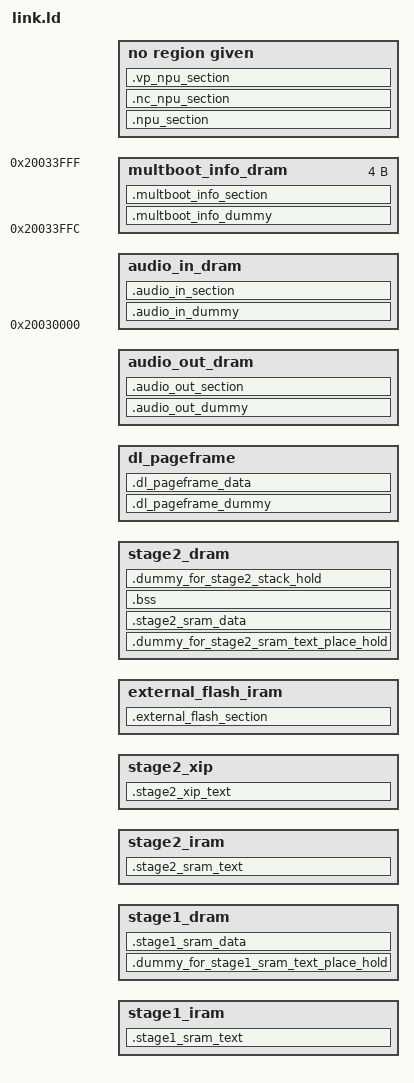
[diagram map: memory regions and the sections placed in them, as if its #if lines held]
#include<autoconf.h>
#include<autogenerated_config.h>
#include<board_config.h>
#include<base_addr.h>
#include<lib/sizes.h>

#ifdef CONFIG_BOOT_BY_UART
#define HEAD_LENGTH 0
#define STAGE2_HEAD_LENGTH 0
#else
#define HEAD_LENGTH 24
#define STAGE2_HEAD_LENGTH 4
#endif

#ifdef CONFIG_BOARD_SUPPORT_MULTIBOOT
#define MULTIBOOT_INFO_SIZE 4
#endif

#define STAGE2_TEXT       *(.text*)
#define STAGE2_DATA       *(.data*)
#define STAGE2_RODATA     *(.rodata*)
#define STAGE2_XIP_TEXT   *(.xip.text)
#define STAGE2_XIP_RODATA *(.xip.rodata*)

# define RUN_AT_STAGE2_TEXT (tmp_objs/vic.o \
                            CONFIG_BOARD_PATH/clock_board.o \
                            tmp_objs/flash_spi.o \
                            tmp_objs/spi_nor_ids.o \
                            tmp_objs/flash.o  \
                            tmp_objs/pmu_ctrl.o \
                            tmp_objs/pmu_osc.o \
                            tmp_objs/ldo.o \
                            tmp_objs/clock.o \
                            arch/cpu/csky/ck804/start.o \
                            arch/cpu/csky/ck804/spl_start.o \
                            arch/soc/grus/system.o \
                            arch/soc/grus/trap_c.o \
                            arch/soc/grus/vectors.o \
                            tmp_objs/systick_counter.o \
                            tmp_objs/gx_counter.o \
                            tmp_objs/gx_dcache.o \
                            utility/libc/csky/memcpy.o \
                            utility/libc/csky/memcpy_fast.o \
                            utility/libc/csky/memset.o \
                            utility/libc/csky/memset_fast.o \
                            utility/libm/csky/ef_exp.o \
                            utility/libm/csky/wf_exp.o \
                            tmp_objs/gx_icache.o)

/* LMA */
#ifdef CONFIG_MCU_ENABLE_JTAG_DEBUG
# define STAGE1_SRAM_TEXT_LMA
# define STAGE1_SRAM_DATA_LMA
# define STAGE2_XIP_TEXT_LMA
# define STAGE2_SRAM_TEXT_LMA
# define STAGE2_SRAM_DATA_LMA
# define NPU_LMA
# define NC_NPU_LMA
# define VP_NPU_LMA
# define EXTERNAL_FLASH_LMA
    LD_NPU_IMAGE_OFFSET     =    0;
    LD_NC_NPU_IMAGE_OFFSET  =    0;
    LD_VP_NPU_IMAGE_OFFSET  =    0;
    LD_MCU_END_IMAGE_OFFSET =    0;
#else
# define STAGE1_SRAM_TEXT_LMA   AT(0)
# define STAGE1_SRAM_DATA_LMA   AT(SIZEOF(.stage1_sram_text))

# ifdef CONFIG_MCU_ENABLE_XIP

#  define STAGE2_XIP_TEXT_LMA   AT(LENGTH(stage1_dram)+STAGE2_HEAD_LENGTH-HEAD_LENGTH)
#  define STAGE2_SRAM_TEXT_LMA  AT(LENGTH(stage1_dram)+STAGE2_HEAD_LENGTH-HEAD_LENGTH+SIZEOF(.stage2_xip_text))
#  define STAGE2_SRAM_DATA_LMA  AT(LENGTH(stage1_dram)+STAGE2_HEAD_LENGTH-HEAD_LENGTH+SIZEOF(.stage2_xip_text)+SIZEOF(.stage2_sram_text))
#  define NPU_LMA               AT(LENGTH(stage1_dram)+STAGE2_HEAD_LENGTH-HEAD_LENGTH+SIZEOF(.stage2_xip_text)+SIZEOF(.stage2_sram_text)+SIZEOF(.stage2_sram_data))
#  define NC_NPU_LMA            AT(LENGTH(stage1_dram)+STAGE2_HEAD_LENGTH-HEAD_LENGTH+SIZEOF(.stage2_xip_text)+SIZEOF(.stage2_sram_text)+SIZEOF(.stage2_sram_data) \
                                    +SIZEOF(.npu_section))
#  define VP_NPU_LMA            AT(LENGTH(stage1_dram)+STAGE2_HEAD_LENGTH-HEAD_LENGTH+SIZEOF(.stage2_xip_text)+SIZEOF(.stage2_sram_text)+SIZEOF(.stage2_sram_data) \
                                    +SIZEOF(.npu_section)+SIZEOF(.nc_npu_section))
#  define EXTERNAL_FLASH_LMA    AT(0x80000 -HEAD_LENGTH)

#  ifndef CONFIG_NPU_RUN_IN_FLASH
        LD_NPU_IMAGE_OFFSET    =    LENGTH(stage1_dram)+STAGE2_HEAD_LENGTH+SIZEOF(.stage2_xip_text)+SIZEOF(.stage2_sram_text)+SIZEOF(.stage2_sram_data);

        LD_NC_NPU_IMAGE_OFFSET =    LENGTH(stage1_dram)+STAGE2_HEAD_LENGTH+SIZEOF(.stage2_xip_text)+SIZEOF(.stage2_sram_text)+SIZEOF(.stage2_sram_data)
#   ifdef CONFIG_LVP_ENABLE_KEYWORD_RECOGNITION
                                    +SIZEOF(.npu_section)
#   endif
                                    ;

        LD_VP_NPU_IMAGE_OFFSET =    LENGTH(stage1_dram)+STAGE2_HEAD_LENGTH+SIZEOF(.stage2_xip_text)+SIZEOF(.stage2_sram_text)+SIZEOF(.stage2_sram_data)
#   ifdef CONFIG_LVP_ENABLE_KEYWORD_RECOGNITION
                                    +SIZEOF(.npu_section)
#   endif
#   if (defined CONFIG_LVP_ENABLE_NN_DENOISE) || (defined CONFIG_LVP_ENABLE_SED)
                                    +SIZEOF(.nc_npu_section)
#   endif
                                    ;
#  endif

   LD_MCU_END_IMAGE_OFFSET     =    LENGTH(stage1_dram)+STAGE2_HEAD_LENGTH+SIZEOF(.stage2_xip_text)+SIZEOF(.stage2_sram_text)+SIZEOF(.stage2_sram_data)
#  ifndef CONFIG_NPU_RUN_IN_FLASH
#   ifdef CONFIG_LVP_ENABLE_KEYWORD_RECOGNITION
                                    +SIZEOF(.npu_section)
#   endif
#   if (defined CONFIG_LVP_ENABLE_NN_DENOISE) || (defined CONFIG_LVP_ENABLE_SED)
                                    +SIZEOF(.nc_npu_section)
#   endif
#   ifdef CONFIG_LVP_ENABLE_VOICEPRINT_RECOGNITION
                                    +SIZEOF(.vp_npu_section)
#   endif
#  endif
                                    ;

# else
#  define STAGE2_XIP_TEXT_LMA
#  define STAGE2_SRAM_TEXT_LMA  AT(LENGTH(stage1_dram)+STAGE2_HEAD_LENGTH-HEAD_LENGTH)
#  define STAGE2_SRAM_DATA_LMA  AT(LENGTH(stage1_dram)+STAGE2_HEAD_LENGTH-HEAD_LENGTH+SIZEOF(.stage2_sram_text))
#  define NPU_LMA               AT(LENGTH(stage1_dram)+STAGE2_HEAD_LENGTH-HEAD_LENGTH+SIZEOF(.stage2_sram_text)+SIZEOF(.stage2_sram_data))
#  define NC_NPU_LMA            AT(LENGTH(stage1_dram)+STAGE2_HEAD_LENGTH-HEAD_LENGTH+SIZEOF(.stage2_sram_text)+SIZEOF(.stage2_sram_data)\
                                    +SIZEOF(.npu_section))
#  define VP_NPU_LMA            AT(LENGTH(stage1_dram)+STAGE2_HEAD_LENGTH-HEAD_LENGTH+SIZEOF(.stage2_sram_text)+SIZEOF(.stage2_sram_data)\
                                    +SIZEOF(.npu_section)+SIZEOF(.nc_npu_section))
#  define EXTERNAL_FLASH_LMA    AT(0x80000 +STAGE2_HEAD_LENGTH-HEAD_LENGTH)

#  ifndef CONFIG_NPU_RUN_IN_FLASH
        LD_NPU_IMAGE_OFFSET    =    LENGTH(stage1_dram)+STAGE2_HEAD_LENGTH+SIZEOF(.stage2_sram_text)+SIZEOF(.stage2_sram_data);

        LD_NC_NPU_IMAGE_OFFSET =    LENGTH(stage1_dram)+STAGE2_HEAD_LENGTH+SIZEOF(.stage2_sram_text)+SIZEOF(.stage2_sram_data)
#   ifdef CONFIG_LVP_ENABLE_KEYWORD_RECOGNITION
                                    +SIZEOF(.npu_section)
#   endif
                                    ;

        LD_VP_NPU_IMAGE_OFFSET =    LENGTH(stage1_dram)+STAGE2_HEAD_LENGTH+SIZEOF(.stage2_sram_text)+SIZEOF(.stage2_sram_data)
#   ifdef CONFIG_LVP_ENABLE_KEYWORD_RECOGNITION
                                    +SIZEOF(.npu_section)
#   endif
#   if (defined CONFIG_LVP_ENABLE_NN_DENOISE) || (defined CONFIG_LVP_ENABLE_SED)
                                    +SIZEOF(.nc_npu_section)
#   endif
                                    ;

    LD_MCU_END_IMAGE_OFFSET     =    LENGTH(stage1_dram)+STAGE2_HEAD_LENGTH+SIZEOF(.stage2_sram_text)+SIZEOF(.stage2_sram_data)
#   ifdef CONFIG_LVP_ENABLE_KEYWORD_RECOGNITION
                                    +SIZEOF(.npu_section)
#   endif
#   if (defined CONFIG_LVP_ENABLE_NN_DENOISE) || (defined CONFIG_LVP_ENABLE_SED)
                                    +SIZEOF(.nc_npu_section)
#   endif
#   ifdef CONFIG_LVP_ENABLE_VOICEPRINT_RECOGNITION
                                    +SIZEOF(.vp_npu_section)
#   endif
                                    ;

#  endif
# endif
#endif

#ifdef CONFIG_DL
   LD_EXT_FLASH_IMAGE_SIZE =   LENGTH(external_flash_iram);
#endif

ENTRY(spl_reset_handler);

MEMORY
{
    stage1_iram : ORIGIN = CONFIG_STAGE1_IRAM_BASE, LENGTH = CONFIG_STAGE1_IRAM_SIZE
    stage1_dram : ORIGIN = CONFIG_STAGE1_DRAM_BASE, LENGTH = CONFIG_STAGE1_DRAM_SIZE
    stage2_iram : ORIGIN = CONFIG_STAGE2_IRAM_BASE, LENGTH = CONFIG_STAGE2_IRAM_SIZE
#ifdef CONFIG_MCU_ENABLE_XIP
# ifdef CONFIG_MULTIBOOT_SECOND_BIN
    stage2_xip  : ORIGIN = CONFIG_STAGE2_XIP_BASE + CONFIG_SECOND_BIN_OFFSET + STAGE2_HEAD_LENGTH,  LENGTH = CONFIG_STAGE2_XIP_SIZE
# else
    stage2_xip  : ORIGIN = CONFIG_STAGE2_XIP_BASE + STAGE2_HEAD_LENGTH,  LENGTH = CONFIG_STAGE2_XIP_SIZE
# endif
#endif
#ifdef CONFIG_DL
    external_flash_iram : ORIGIN = CONFIG_EXTERNAL_FLASH_BASE, LENGTH = CONFIG_EXTERNAL_FLASH_SZIE
#endif
    stage2_dram : ORIGIN = CONFIG_STAGE2_DRAM_BASE, LENGTH = CONFIG_STAGE2_DRAM_SIZE
    dl_pageframe : ORIGIN = CONFIG_DL_PAGEFRAME_BASE, LENGTH = CONFIG_DL_SIZE
    audio_out_dram : ORIGIN = 0x20030000 - CONFIG_AUDIO_OUT_BUFFER_SIZE, LENGTH = CONFIG_AUDIO_OUT_BUFFER_SIZE
#ifdef CONFIG_BOARD_SUPPORT_MULTIBOOT
    audio_in_dram : ORIGIN = 0x20030000, LENGTH = 0x4000 - SIZEOF(.multboot_info_dram)      /* audio_in 固定从0x20030000地址开始 */
    multboot_info_dram : ORIGIN = 0x20034000 - MULTIBOOT_INFO_SIZE, LENGTH = MULTIBOOT_INFO_SIZE
#else
    audio_in_dram : ORIGIN = 0x20030000, LENGTH = 0x4000       /* audio_in 固定从0x20030000地址开始 */
#endif
}

SECTIONS
{
    .stage1_sram_text : STAGE1_SRAM_TEXT_LMA
    {
        . = ALIGN(4);
        _stage1_sram_start_text_ = .;
        arch/cpu/csky/ck804/spl_start.o(.spl.vectors*)
        arch/cpu/csky/ck804/spl_start.o(.text*)
        arch/soc/grus/spl/spl*.o(.text*)
        CONFIG_BOARD_PATH/boot_board.o(.text*)

        arch/cpu/csky/ck804/spl_start.o(.rodata*)
        arch/soc/grus/spl/spl*.o(.rodata*)
        CONFIG_BOARD_PATH/boot_board.o(.rodata*)

        . = ALIGN(4);
        _stage1_sram_end_text = .;
    } > stage1_iram

    .dummy_for_stage1_sram_text_place_hold :
    {
        . += SIZEOF(.stage1_sram_text);
    } > stage1_dram

    .stage1_sram_data ALIGN(4) : STAGE1_SRAM_DATA_LMA
    {
        . = ALIGN(4);
        _stage1_sram_start_data_ = .;
        arch/cpu/csky/ck804/spl_start.o(.data*)
        arch/soc/grus/spl/spl*.o(.data*)
        CONFIG_BOARD_PATH/boot_board.o(.data*)

        . = ALIGN(4);
        _stage1_sram_end_data_ = .;
    } > stage1_dram

    . = ALIGN(2048);

#ifdef CONFIG_MCU_ENABLE_XIP
    .stage2_xip_text : STAGE2_XIP_TEXT_LMA
    {
        _stage2_xip_start_text_ = .;
        STAGE2_XIP_TEXT
        STAGE2_XIP_RODATA
# ifdef CONFIG_MCU_DEFAULT_TEXT_IN_FLASH
        *(EXCLUDE_FILE RUN_AT_STAGE2_TEXT .text*)
        *(EXCLUDE_FILE RUN_AT_STAGE2_TEXT .rodata*)
#  ifdef CONFIG_SYSTICK_COUNTER
        tmp_objs/gx_counter.o(.rodata*)
#  elif defined CONFIG_GX_COUNTER
        tmp_objs/gx_counter.o(.rodata*)
#  endif
        tmp_objs/gx_icache.o(.rodata*)
        tmp_objs/gx_dcache.o(.rodata*)
        tmp_objs/vic.o(.rodata*)
        tmp_objs/flash.o(.rodata*)
        tmp_objs/flash_spi.o(.rodata*)
        tmp_objs/spi_nor_ids.o(.rodata*)
        tmp_objs/ldo.o(.rodata*)
# endif

# ifdef CONFIG_KWS_TYPE_HYBRID
        . = ALIGN(4);
        KEEP(*(.xip_cmd*))
        . = ALIGN(4);
        KEEP(*(.xip_weight*))
        . = ALIGN(4);
        KEEP(*(.xip_npu_section*))
# endif

# ifdef CONFIG_NPU_RUN_IN_FLASH
        . = ALIGN(4);
        KEEP(*(.cmd*))
        . = ALIGN(4);
        KEEP(*(.weight*))
        . = ALIGN(4);
        KEEP(*(.npu_section*))
        . = ALIGN(4);
        KEEP(*(.vp_cmd*))
        . = ALIGN(4);
        KEEP(*(.vp_weight*))
        . = ALIGN(4);
        KEEP(*(.vp_npu_section*))
# endif
        . = ALIGN(4);
        _stage2_xip_end_text_ = .;
    } > stage2_xip
#endif /* CONFIG_MCU_ENABLE_XIP */

    .stage2_sram_text : STAGE2_SRAM_TEXT_LMA
    {
        _stage2_sram_start_text_ = .;
        arch/cpu/csky/ck804/start.o(.vectors*)
        arch/cpu/csky/ck804/start.o(.text*)
        arch/cpu/csky/ck804/spl_start.o(.rodata*)
#ifdef CONFIG_MCU_DEFAULT_TEXT_IN_FLASH
        arch/soc/grus/system.o(.text*)
        arch/soc/grus/system.o(.rodata*)
        arch/soc/grus/trap_c.o(.text*)
        arch/soc/grus/trap_c.o(.rodata*)
        arch/soc/grus/vectors.o(.text*)
        arch/soc/grus/vectors.o(.rodata*)
        tmp_objs/flash_spi.o(.text*)
        tmp_objs/spi_nor_ids.o(.text*)
        tmp_objs/ldo.o(.text*)
        tmp_objs/flash.o(.text*)
        tmp_objs/pmu_ctrl.o(.text*)
        tmp_objs/pmu_ctrl.o(.rodata*)
        tmp_objs/pmu_osc.o(.text*)
        tmp_objs/pmu_osc.o(.rodata*)
        tmp_objs/clock.o(.text*)
        tmp_objs/clock.o(.rodata*)
        tmp_objs/vic.o(.text*)
        tmp_objs/gx_dcache.o(.text*)
        tmp_objs/gx_icache.o(.text*)
        utility/libc/csky/memcpy.o(.text*)
        utility/libc/csky/memcpy_fast.o(.text*)
# ifdef CONFIG_LVP_DISABLE_XIP_WHILE_CODE_RUN_AT_SRAM
        utility/libc/csky/memset.o(.text*)
        utility/libc/csky/memset_fast.o(.text*)
        utility/libm/csky/ef_exp.o(.text*)
        utility/libm/csky/ef_exp.o(.rodata*)
        utility/libm/csky/wf_exp.o(.text*)
        utility/libm/csky/wf_exp.o(.rodata*)
# endif
# if defined CONFIG_SYSTICK_COUNTER
        tmp_objs/gx_counter.o(.text*)
# elif defined CONFIG_GX_COUNTER
        tmp_objs/gx_counter.o(.text*)
# endif
        CONFIG_BOARD_PATH/clock_board.o(.text*)
        CONFIG_BOARD_PATH/clock_board.o(.rodata*)
#else
        STAGE2_TEXT
        STAGE2_RODATA
#endif
        *(.sram_text*)
        . = ALIGN(4);
        _stage2_sram_end_text_ = .;
    } > stage2_iram

    .dummy_for_stage2_sram_text_place_hold :
    {
        . += SIZEOF(.stage2_sram_text);
    } > stage2_dram

    .stage2_sram_data ALIGN(4) : STAGE2_SRAM_DATA_LMA
    {
        _stage2_sram_start_data_ = .;
        arch/cpu/csky/ck804/start.o(.data*)
        STAGE2_DATA
        _stage2_sram_end_data_ = .;
    } > stage2_dram

    . = ALIGN(4);
    .bss :
    {
        _start_bss_ = .;
        *(.bss)
        *(COMMON)
        . = ALIGN(4);
        _end_bss_ = .;
    } > stage2_dram

    .dummy_for_stage2_stack_hold :
    {
        _start_stack_section_ = .;
        . += CONFIG_MCU_MAIN_STACK_SIZE * 1024;
        _end_stack_section_ = .;
    } > stage2_dram

    .dl_pageframe_dummy :
    {
        . += .;
    } > dl_pageframe

    . = ALIGN(16);
    .dl_pageframe_data :
    {
        _dl_pageframe_start_data_ = .;
        . += CONFIG_DL_SIZE;
        _dl_pageframe_end_data_ = .;
    } > dl_pageframe

    .audio_out_dummy :
    {
        . += .;
    } > audio_out_dram

    . = ALIGN(16);
    .audio_out_section ALIGN(16):
    {
        _start_audio_out_section_ = .;
        KEEP(*(.audio_out*))
        _end_audio_out_section_ = .;
    } > audio_out_dram

    .audio_in_dummy :
    {
        . += .;
    } > audio_in_dram

    . = ALIGN(4);
    .audio_in_section ALIGN(4):
    {
        _start_audio_in_section_ = .;
        KEEP(*(.audio_in*))
        _end_audio_in_section_ = .;
    } > audio_in_dram

#ifdef CONFIG_BOARD_SUPPORT_MULTIBOOT
    .multboot_info_dummy :
    {
        . += .;
    } > multboot_info_dram

    .multboot_info_section ALIGN(4):
    {
        _multboot_info_addr_ = .;
        KEEP(*(.mode_addr*))
    } > multboot_info_dram
#endif

#ifndef CONFIG_NPU_RUN_IN_FLASH

# ifdef CONFIG_LVP_ENABLE_KEYWORD_RECOGNITION
    . = ALIGN(4);
    .npu_section ALIGN(4): NPU_LMA
    {
        _start_npu_section_ = .;
        KEEP(*(.cmd*))
        . = ALIGN(4);
        KEEP(*(.weight*))
        . = ALIGN(4);
        _end_npu_section_ = .;
    }
# endif

# if (defined CONFIG_LVP_ENABLE_NN_DENOISE) || (defined CONFIG_LVP_ENABLE_SED)
    . = ALIGN(4);
    .nc_npu_section ALIGN(4): NC_NPU_LMA
    {
        _start_nc_npu_section_ = .;
        KEEP(*(.nc_cmd*))
        . = ALIGN(4);
        KEEP(*(.nc_weight*))
        . = ALIGN(4);
        _end_nc_npu_section_ = .;
    }
# endif

# ifdef CONFIG_LVP_ENABLE_VOICEPRINT_RECOGNITION
    . = ALIGN(4);
    .vp_npu_section ALIGN(4): VP_NPU_LMA
    {
        _start_vp_npu_section_ = .;
        KEEP(*(.vp_cmd*))
        . = ALIGN(4);
        KEEP(*(.vp_weight*))
        . = ALIGN(4);
        _end_vp_npu_section_ = .;
    }
# endif
#endif /* CONFIG_MCU_ENABLE_XIP */

# ifdef CONFIG_DL
    . = ALIGN(4);
    .external_flash_section : EXTERNAL_FLASH_LMA
    {
        _start_external_flash_section_ = .;
        KEEP(*(.external_flash.text))
        . = ALIGN(4);
        KEEP(*(.external_flash.rodata))
        . = ALIGN(4);
        _end_external_flash_section_ = .;
    } > external_flash_iram
# endif

}
